# PWMSS1_EQEP_local register map
Vendor: Texas Instruments
Peripheral module from a debugger description file (folder DRA72x).
Registers are 16-bit, read-write, reset 0x0 unless marked. A register's access mark holds for its fields unless they carry their own. Offsets are as the file gives them; lines under a group give offsets from that group; [hi:lo] are bit positions; {n}, {i} and the like mark numbered series; 'fields as' and 'values as' point back to an identical list; <NAME> marks a mode.

## PWMSS1_EQEP
0x00 EQEP_QPOSCNT 32-bit
  [31:0] QPOSCNT — This 32 bit position counter register counts up/down on every eQEP pulse based on direction input. This counter acts as a position integrator whose count value is proportional to position from a give reference point.
0x04 EQEP_QPOSINIT 32-bit
  [31:0] QPOSINIT — This register contains the position value that is used to initialize the position counter based on external strobe or index event. The position counter can be initialized through software.
0x08 EQEP_QPOSMAX 32-bit
  [31:0] QPOSMAX — This register contains the maximum position counter value.
0x0C EQEP_QPOSCMP 32-bit
  [31:0] QPOSCMP — The position-compare value in this register is compared with the position counter (QPOSCNT field in
0x10 EQEP_QPOSILAT 32-bit ro
  [31:0] QPOSILAT — The position-counter value is latched into this register on an index event as defined by the QEPCTL[IEL] bits.
0x14 EQEP_QPOSSLAT 32-bit ro
  [31:0] QPOSSLAT — The position-counter value is latched into this register on strobe event as defined by the QEPCTL[SEL] bits.
0x18 EQEP_QPOSLAT 32-bit ro
  [31:0] QPOSLAT — The position-counter value is latched into this register on unit time out event.
0x1C EQEP_QUTMR 32-bit
  [31:0] QUTMR — This register acts as time base for unit time event generation. When this timer value matches with unit time period value, unit time event is generated.
0x20 EQEP_QUPRD 32-bit
  [31:0] QUPRD — This register contains the period count for unit timer to generate periodic unit time events to latch the eQEP position information at periodic interval and optionally to generate interrupt.
0x24 EQEP_QWDTMR
  [15:0] QWDTMR — This register acts as time base for watch dog to detect motor stalls. When this timer value matches with watch dog period value, watch dog timeout interrupt is generated. This register is reset upon edge transition in quadrature-clock indicating the motion.
0x26 EQEP_QWDPRD
  [15:0] QWDPRD — This register contains the time-out count for the eQEP peripheral watch dog timer. When the watchdog timer value matches the watchdog period value, a watchdog timeout interrupt is generated.
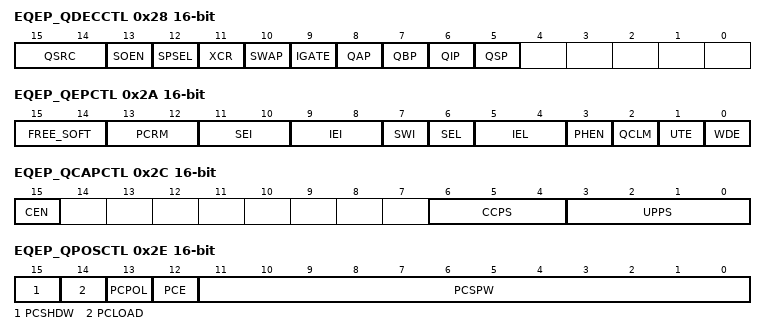
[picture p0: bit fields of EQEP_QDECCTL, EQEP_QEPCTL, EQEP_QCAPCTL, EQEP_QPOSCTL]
0x28 EQEP_QDECCTL access per field
  [15:14] QSRC rw — Position-counter source selection. 0x0 = Quadrature count mode (QCLK = iCLK, QDIR = iDIR) 0x1 = Direction-count mode (QCLK = xCLK, QDIR = xDIR) 0x2 = UP count mode for frequency measurement (QCLK = xCLK, QDIR = 1) 0x3 = DOWN count mode for frequency measurement (QCLK = xCLK, QDIR = 0)
  [13] SOEN rw — Sync output-enable 0x0 = Disable position-compare sync output 0x1 = Enable position-compare sync output
  [12] SPSEL rw — Sync output pin selection 0x0 = Index pin is used for sync output 0x1 = Strobe pin is used for sync output
  [11] XCR rw — External clock rate 0x0 = 2x resolution: Count the rising/falling edge 0x1 = 1x resolution: Count the rising edge only
  [10] SWAP rw — Swap quadrature clock inputs. This swaps the input to the quadrature decoder, reversing the counting direction. 0x0 = Quadrature-clock inputs are not swapped 0x1 = Quadrature-clock inputs are swapped
  [9] IGATE rw — Index pulse gating option 0x0 = Disable gating of Index pulse 0x1 = Gate the index pin with strobe
  [8] QAP rw — QEPA input polarity 0x0 = No effect 0x1 = Negates QEPA input
  [7] QBP rw — QEPB input polarity 0x0 = No effect 0x1 = Negates QEPB input
  [6] QIP rw — QEPI input polarity 0x0 = No effect 0x1 = Negates QEPI input
  [5] QSP rw — QEPS input polarity 0x0 = No effect 0x1 = Negates QEPS input
0x2A EQEP_QEPCTL
  [15:14] FREE_SOFT — Emulation Control Bits. In the values 0 through 3 listed below, x is different for the four following behaviors. 0x0 = x stops immediately. For QPOSCNT behavior, the stop is on emulation suspend. 0x1 = x continues to count until the rollover. 0x2 = x is unaffected by emulation suspend. 0x3 = x is unaffected by emulation suspend.
  [13:12] PCRM — Position counter reset mode 0x0 = Position counter reset on an index event 0x1 = Position counter reset on the maximum position 0x2 = Position counter reset on the first index event 0x3 = Position counter reset on a unit time event
  [11:10] SEI — Strobe event initialization of position counter 0x0 = Does nothing (action disabled) 0x1 = Does nothing (action disabled) 0x2 = Initializes the position counter on rising edge of the QEPS signal 0x3 = Clockwise Direction: Initializes the position counter on the rising edge of QEPS strobe. Counter Clockwise Direction: Initializes the position counter on the falling edge of QEPS strobe
  [9:8] IEI — Index event initialization of position counter 0x0 = Do nothing (action disabled) 0x1 = Do nothing (action disabled) 0x2 = Initializes the position counter on the rising edge of the QEPI signal (QPOSCNT = QPOSINIT) 0x3 = Initializes the position counter on the falling edge of QEPI signal (QPOSCNT = QPOSINIT)
  [7] SWI — Software initialization of position counter 0x0 = Do nothing (action disabled) 0x1 = Initialize position counter, this bit is cleared automatically
  [6] SEL — Strobe event latch of position counter 0x0 = The position counter is latched on the rising edge of QEPS strobe (QPOSSLAT = POSCCNT). Latching on the falling edge can be done by inverting the strobe input using the QSP bit in the 0x1 = Clockwise Direction: Position counter is latched on rising edge of QEPS strobe. Counter Clockwise Direction: Position counter is latched on falling edge of QEPS strobe.
  [5:4] IEL — Index event latch of position counter (software index marker) 0x0 = Reserved 0x1 = Latches position counter on rising edge of the index signal 0x2 = Latches position counter on falling edge of the index signal 0x3 = Software index marker. Latches the position counter and quadrature direction flag on index event marker. The position counter is latched to the
  [3] PHEN — Quadrature position counter enable/software reset 0x0 = Reset the eQEP peripheral internal operating flags/read-only registers. Control/configuration registers are not disturbed by a software reset. 0x1 = eQEP position counter is enabled
  [2] QCLM — eQEP capture latch mode 0x0 = Latch on position counter read by CPU. Capture timer and capture period values are latched into 0x1 = Latch on unit time out. Position counter, capture timer and capture period values are latched into
  [1] UTE — eQEP unit timer enable 0x0 = Disable eQEP unit timer 0x1 = Enable unit timer
  [0] WDE — eQEP watchdog enable 0x0 = Disable the eQEP watchdog timer 0x1 = Enable the eQEP watchdog timer
0x2C EQEP_QCAPCTL access per field
  [15] CEN rw — Enable eQEP capture 0x0 = eQEP capture unit is disabled 0x1 = eQEP capture unit is enabled
  [6:4] CCPS rw — eQEP capture timer clock prescaler 0x0 = CAPCLK = SYSCLKOUT/1 0x1 = CAPCLK = SYSCLKOUT/2 0x2 = CAPCLK = SYSCLKOUT/4 0x3 = CAPCLK = SYSCLKOUT/8 0x4 = CAPCLK = SYSCLKOUT/16 0x5 = CAPCLK = SYSCLKOUT/32 0x6 = CAPCLK = SYSCLKOUT/64 0x7 = CAPCLK = SYSCLKOUT/128
  [3:0] UPPS rw — Unit position event prescaler 0x0 = UPEVNT = QCLK/1 0x1 = UPEVNT = QCLK/2 0x2 = UPEVNT = QCLK/4 0x3 = UPEVNT = QCLK/8 0x4 = UPEVNT = QCLK/16 0x5 = UPEVNT = QCLK/32 0x6 = UPEVNT = QCLK/64 0x7 = UPEVNT = QCLK/128 0x8 = UPEVNT = QCLK/256 0x9 = UPEVNT = QCLK/512 0xA = UPEVNT = QCLK/1024 0xB = UPEVNT = QCLK/2048 0xC = Reserved 0xD = Reserved 0xE = Reserved 0xF = Reserved
0x2E EQEP_QPOSCTL
  [15] PCSHDW — Position-compare shadow enable 0x0 = Shadow disabled, load Immediate 0x1 = Shadow enabled
  [14] PCLOAD — Position-compare shadow load mode 0x0 = Load on QPOSCNT = 0 0x1 = Load when QPOSCNT = QPOSCMP
  [13] PCPOL — Polarity of sync output 0x0 = Active HIGH pulse output 0x1 = Active LOW pulse output
  [12] PCE — Position-compare enable/disable 0x0 = Disable position compare unit 0x1 = Enable position compare unit
  [11:0] PCSPW — Select-position-compare sync output pulse width ... 0x0 = 1 x 4 x SYSCLKOUT cycles 0x1 = 2 x 4 x SYSCLKOUT cycles 0x2 = 3 x 4 x SYSCLKOUT cycles to 4096 x 4 x SYSCLKOUT cycles 0xFFF = 3 x 4 x SYSCLKOUT cycles to 4096 x 4 x SYSCLKOUT cycles
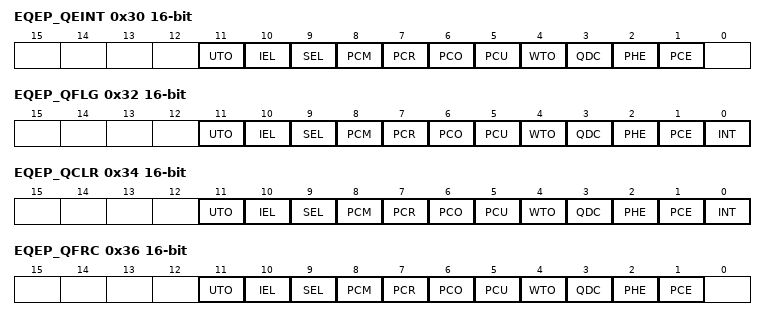
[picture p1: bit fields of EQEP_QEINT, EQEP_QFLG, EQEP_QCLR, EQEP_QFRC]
0x30 EQEP_QEINT access per field
  [11] UTO rw — Unit time out interrupt enable 0x0 = Interrupt is disabled 0x1 = Interrupt is enabled
  [10] IEL rw — Index event latch interrupt enable 0x0 = Interrupt is disabled 0x1 = Interrupt is enabled
  [9] SEL rw — Strobe event latch interrupt enable 0x0 = Interrupt is disabled 0x1 = Interrupt is enabled
  [8] PCM rw — Position-compare match interrupt enable 0x0 = Interrupt is disabled 0x1 = Interrupt is enabled
  [7] PCR rw — Position-compare ready interrupt enable 0x0 = Interrupt is disabled 0x1 = Interrupt is enabled
  [6] PCO rw — Position counter overflow interrupt enable 0x0 = Interrupt is disabled 0x1 = Interrupt is enabled
  [5] PCU rw — Position counter underflow interrupt enable 0x0 = Interrupt is disabled 0x1 = Interrupt is enabled
  [4] WTO rw — Watchdog time out interrupt enable 0x0 = Interrupt is disabled 0x1 = Interrupt is enabled
  [3] QDC rw — Quadrature direction change interrupt enable 0x0 = Interrupt is disabled 0x1 = Interrupt is enabled
  [2] PHE rw — Quadrature phase error interrupt enable 0x0 = Interrupt is disabled 0x1 = Interrupt is enabled
  [1] PCE rw — Position counter error interrupt enable 0x0 = Interrupt is disabled 0x1 = Interrupt is enabled
0x32 EQEP_QFLG ro
  [11] UTO — Unit time out interrupt flag 0x0 = No interrupt generated 0x1 = Set by eQEP unit timer period match
  [10] IEL — Index event latch interrupt flag 0x0 = No interrupt generated 0x1 = This bit is set after latching the QPOSCNT to QPOSILAT
  [9] SEL — Strobe event latch interrupt flag 0x0 = No interrupt generated 0x1 = This bit is set after latching the QPOSCNT to
  [8] PCM — eQEP compare match event interrupt flag 0x0 = No interrupt generated 0x1 = This bit is set on position-compare match
  [7] PCR — Position-compare ready interrupt flag 0x0 = No interrupt generated 0x1 = This bit is set after transferring the shadow register value to the active position compare register.
  [6] PCO — Position counter overflow interrupt flag 0x0 = No interrupt generated 0x1 = This bit is set on position counter overflow.
  [5] PCU — Position counter underflow interrupt flag 0x0 = No interrupt generated 0x1 = This bit is set on position counter underflow.
  [4] WTO — Watchdog timeout interrupt flag 0x0 = No interrupt generated 0x1 = Set by watch dog timeout
  [3] QDC — Quadrature direction change interrupt flag 0x0 = No interrupt generated 0x1 = This bit is set during change of direction
  [2] PHE — Quadrature phase error interrupt flag 0x0 = No interrupt generated 0x1 = Set on simultaneous transition of QEPA and QEPB
  [1] PCE — Position counter error interrupt flag 0x0 = No interrupt generated 0x1 = Position counter error
  [0] INT — Global interrupt status flag 0x0 = No interrupt generated 0x1 = Interrupt was generated
0x34 EQEP_QCLR access per field
  [11] UTO rw — Clear unit time out interrupt flag 0x0 = No effect 0x1 = Clears the interrupt flag
  [10] IEL rw — Clear index event latch interrupt flag 0x0 = No effect 0x1 = Clears the interrupt flag
  [9] SEL rw — Clear strobe event latch interrupt flag 0x0 = No effect 0x1 = Clears the interrupt flag
  [8] PCM rw — Clear eQEP compare match event interrupt flag 0x0 = No effect 0x1 = Clears the interrupt flag
  [7] PCR rw — Clear position-compare ready interrupt flag 0x0 = No effect 0x1 = Clears the interrupt flag
  [6] PCO rw — Clear position counter overflow interrupt flag 0x0 = No effect 0x1 = Clears the interrupt flag
  [5] PCU rw — Clear position counter underflow interrupt flag 0x0 = No effect 0x1 = Clears the interrupt flag
  [4] WTO rw — Clear watchdog timeout interrupt flag 0x0 = No effect 0x1 = Clears the interrupt flag
  [3] QDC rw — Clear quadrature direction change interrupt flag 0x0 = No effect 0x1 = Clears the interrupt flag
  [2] PHE rw — Clear quadrature phase error interrupt flag 0x0 = No effect 0x1 = Clears the interrupt flag
  [1] PCE rw — Clear position counter error interrupt flag 0x0 = No effect 0x1 = Clears the interrupt flag
  [0] INT rw — Global interrupt clear flag 0x0 = No effect 0x1 = Clears the interrupt flag and enables further interrupts to be generated if an event flags is set to 1.
0x36 EQEP_QFRC access per field
  [11] UTO rw — Force unit time out interrupt 0x0 = No effect 0x1 = Force the interrupt
  [10] IEL rw — Force index event latch interrupt 0x0 = No effect 0x1 = Force the interrupt
  [9] SEL rw — Force strobe event latch interrupt 0x0 = No effect 0x1 = Force the interrupt
  [8] PCM rw — Force position-compare match interrupt 0x0 = No effect 0x1 = Force the interrupt
  [7] PCR rw — Force position-compare ready interrupt 0x0 = No effect 0x1 = Force the interrupt
  [6] PCO rw — Force position counter overflow interrupt 0x0 = No effect 0x1 = Force the interrupt
  [5] PCU rw — Force position counter underflow interrupt 0x0 = No effect 0x1 = Force the interrupt
  [4] WTO rw — Force watchdog time out interrupt 0x0 = No effect 0x1 = Force the interrupt
  [3] QDC rw — Force quadrature direction change interrupt 0x0 = No effect 0x1 = Force the interrupt
  [2] PHE rw — Force quadrature phase error interrupt 0x0 = No effect 0x1 = Force the interrupt
  [1] PCE rw — Force position counter error interrupt 0x0 = No effect 0x1 = Force the interrupt
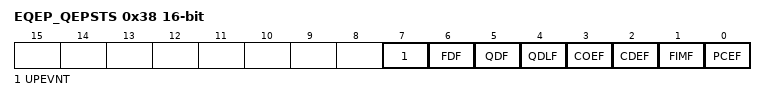
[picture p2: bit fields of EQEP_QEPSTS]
0x38 EQEP_QEPSTS access per field
  [7] UPEVNT ro — Unit position event flag 0x0 = No unit position event detected 0x1 = Unit position event detected. Write 1 to clear.
  [6] FDF ro — Direction on the first index marker. Status of the direction is latched on the first index event marker. 0x0 = Counter-clockwise rotation (or reverse movement) on the first index event 0x1 = Clockwise rotation (or forward movement) on the first index event
  [5] QDF ro — Quadrature direction flag 0x0 = Counter-clockwise rotation (or reverse movement) 0x1 = Clockwise rotation (or forward movement)
  [4] QDLF ro — eQEP direction latch flag. Status of direction is latched on every index event marker. 0x0 = Counter-clockwise rotation (or reverse movement) on index event marker 0x1 = Clockwise rotation (or forward movement) on index event marker
  [3] COEF rw — Capture overflow error flag 0x0 = Sticky bit, cleared by writing 1 0x1 = Overflow occurred in eQEP Capture timer (QEPCTMR)
  [2] CDEF rw — Capture direction error flag 0x0 = Sticky bit, cleared by writing 1 0x1 = Direction change occurred between the capture position event.
  [1] FIMF rw — First index marker flag 0x0 = Sticky bit, cleared by writing 1 0x1 = Set by first occurrence of index pulse
  [0] PCEF ro — Position counter error flag. This bit is not sticky and it is updated for every index event. 0x0 = No error occurred during the last index transition. 0x1 = Position counter error
0x3A EQEP_QCTMR
  [15:0] QCTMR — This register provides time base for edge capture unit.
0x3C EQEP_QCPRD
  [15:0] QCPRD — This register holds the period count value between the last successive eQEP position events
0x3E EQEP_QCTMRLAT ro
  [15:0] QCTMRLAT — The eQEP capture timer value can be latched into this register on two events, that is, unit timeout event, reading the eQEP position counter.
0x40 EQEP_QCPRDLAT
  [15:0] QCPRDLAT — eQEP capture period value can be latched into this register on two events, that is, unit timeout event, reading the eQEP position counter.
0x5C EQEP_REVID 32-bit ro reset not defined
  [31:0] REVISION — IP Revision
